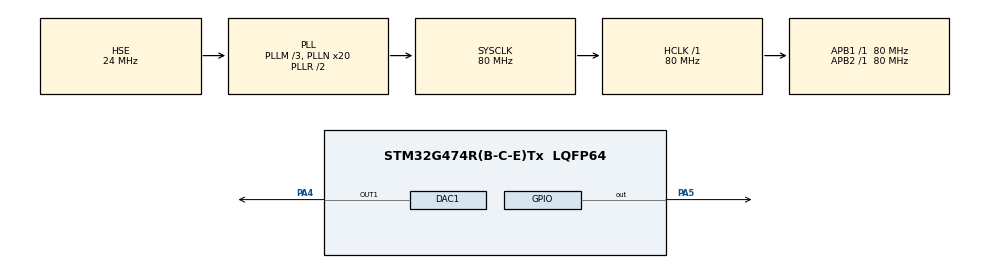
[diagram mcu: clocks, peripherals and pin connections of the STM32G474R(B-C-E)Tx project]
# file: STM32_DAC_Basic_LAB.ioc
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DAC1.DAC_HighFrequency_OUT1-DAC_OUT1=DAC_HIGH_FREQUENCY_INTERFACE_MODE_DISABLE
Mcu.Family=STM32G4
Mcu.Name=STM32G474R(B-C-E)Tx
Mcu.Package=LQFP64
NVIC.PriorityGroup=NVIC_PRIORITYGROUP_4
NVIC.TIM1_UP_TIM16_IRQn=true\:15\:0\:false\:false\:true\:false\:true
NVIC.TimeBase=TIM1_UP_TIM16_IRQn
NVIC.TimeBaseIP=TIM1
PA13.Mode=Serial_Wire
PA13.Signal=SYS_JTMS-SWDIO
PA14.Mode=Serial_Wire
PA14.Signal=SYS_JTCK-SWCLK
PA4.Signal=COMP_DAC11_group
PA5.Signal=GPIO_Output
PF0-OSC_IN.Mode=HSE-External-Oscillator
PF0-OSC_IN.Signal=RCC_OSC_IN
PF1-OSC_OUT.Mode=HSE-External-Oscillator
PF1-OSC_OUT.Signal=RCC_OSC_OUT
ProjectManager.HeapSize=0x200
ProjectManager.StackSize=0x400
ProjectManager.TargetToolchain=STM32CubeIDE
RCC.ADC12Freq_Value=80000000
RCC.ADC345Freq_Value=80000000
RCC.AHBFreq_Value=80000000
RCC.APB1Freq_Value=80000000
RCC.APB1TimFreq_Value=80000000
RCC.APB2Freq_Value=80000000
RCC.APB2TimFreq_Value=80000000
RCC.CortexFreq_Value=80000000
RCC.EXTERNAL_CLOCK_VALUE=12288000
RCC.HCLKFreq_Value=80000000
RCC.HSE_VALUE=24000000
RCC.HSI48_VALUE=48000000
RCC.HSI_VALUE=16000000
RCC.LSE_VALUE=32768
RCC.PLLM=RCC_PLLM_DIV3
RCC.PLLN=20
RCC.PLLSourceVirtual=RCC_PLLSOURCE_HSE
RCC.RTCClockSelection=RCC_RTCCLKSOURCE_LSE
RCC.SYSCLKFreq_VALUE=80000000
RCC.SYSCLKSource=RCC_SYSCLKSOURCE_PLLCLK
RCC.USBFreq_Value=80000000
RCC.VCOOutputFreq_Value=160000000
SH.COMP_DAC11_group.0=DAC1_OUT1,DAC_OUT1
VP_SYS_VS_tim1.Mode=TIM1
board=NUCLEO-G474RE

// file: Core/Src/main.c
/* USER CODE BEGIN Header */
/**
  ******************************************************************************
  * @file           : main.c
  * @brief          : Main program body
  ******************************************************************************
  * @attention
  *
  * <h2><center>&copy; Copyright (c) 2021 STMicroelectronics.
  * All rights reserved.</center></h2>
  *
  * This software component is licensed by ST under BSD 3-Clause license,
  * the "License"; You may not use this file except in compliance with the
  * License. You may obtain a copy of the License at:
  *                        opensource.org/licenses/BSD-3-Clause
  *
  ******************************************************************************
  */
/* USER CODE END Header */
#include "main.h"

DAC_HandleTypeDef hdac1;

void SystemClock_Config(void);
static void MX_GPIO_Init(void);
static void MX_DAC1_Init(void);

int main(void)
{
  /* USER CODE BEGIN 1 */

  float value = 0.2;
  uint32_t var;

  /* USER CODE END 1 */

  /* MCU Configuration--------------------------------------------------------*/

  /* Reset of all peripherals, Initializes the Flash interface and the Systick. */
  HAL_Init();

  /* Configure the system clock */
  SystemClock_Config();

  /* Initialize all configured peripherals */
  MX_GPIO_Init();
  MX_DAC1_Init();
  /* USER CODE BEGIN 2 */
  HAL_DAC_Start(&hdac1, DAC_CHANNEL_1);
  /* USER CODE END 2 */

  /* Infinite loop */
  /* USER CODE BEGIN WHILE */

  while (1)
  {
    var = (uint32_t)(value * (0xfff + 1) / 3.3);
    HAL_DAC_SetValue(&hdac1, DAC_CHANNEL_1, DAC_ALIGN_12B_R, var);
    value += 0.1;
    HAL_Delay(500);
    if (value > 3)
      value = 0.2;
    /* USER CODE END WHILE */

  }
}

void SystemClock_Config(void)
{
  RCC_OscInitTypeDef RCC_OscInitStruct = {0};
  RCC_ClkInitTypeDef RCC_ClkInitStruct = {0};

  /** Configure the main internal regulator output voltage
  */
  HAL_PWREx_ControlVoltageScaling(PWR_REGULATOR_VOLTAGE_SCALE1);
  /** Initializes the RCC Oscillators according to the specified parameters
  * in the RCC_OscInitTypeDef structure.
  */
  RCC_OscInitStruct.OscillatorType = RCC_OSCILLATORTYPE_HSE;
  RCC_OscInitStruct.HSEState = RCC_HSE_ON;
  RCC_OscInitStruct.PLL.PLLState = RCC_PLL_ON;
  RCC_OscInitStruct.PLL.PLLSource = RCC_PLLSOURCE_HSE;
  RCC_OscInitStruct.PLL.PLLM = RCC_PLLM_DIV3;
  RCC_OscInitStruct.PLL.PLLN = 20;
  RCC_OscInitStruct.PLL.PLLP = RCC_PLLP_DIV2;
  RCC_OscInitStruct.PLL.PLLQ = RCC_PLLQ_DIV2;
  RCC_OscInitStruct.PLL.PLLR = RCC_PLLR_DIV2;
  if (HAL_RCC_OscConfig(&RCC_OscInitStruct) != HAL_OK)
  {
    Error_Handler();
  }
  /** Initializes the CPU, AHB and APB buses clocks
  */
  RCC_ClkInitStruct.ClockType = RCC_CLOCKTYPE_HCLK|RCC_CLOCKTYPE_SYSCLK
                              |RCC_CLOCKTYPE_PCLK1|RCC_CLOCKTYPE_PCLK2;
  RCC_ClkInitStruct.SYSCLKSource = RCC_SYSCLKSOURCE_PLLCLK;
  RCC_ClkInitStruct.AHBCLKDivider = RCC_SYSCLK_DIV1;
  RCC_ClkInitStruct.APB1CLKDivider = RCC_HCLK_DIV1;
  RCC_ClkInitStruct.APB2CLKDivider = RCC_HCLK_DIV1;

  if (HAL_RCC_ClockConfig(&RCC_ClkInitStruct, FLASH_LATENCY_2) != HAL_OK)
  {
    Error_Handler();
  }
}

static void MX_DAC1_Init(void)
{

  DAC_ChannelConfTypeDef sConfig = {0};

  /** DAC Initialization
  */
  hdac1.Instance = DAC1;
  if (HAL_DAC_Init(&hdac1) != HAL_OK)
  {
    Error_Handler();
  }
  /** DAC channel OUT1 config
  */
  sConfig.DAC_HighFrequency = DAC_HIGH_FREQUENCY_INTERFACE_MODE_DISABLE;
  sConfig.DAC_DMADoubleDataMode = DISABLE;
  sConfig.DAC_SignedFormat = DISABLE;
  sConfig.DAC_SampleAndHold = DAC_SAMPLEANDHOLD_DISABLE;
  sConfig.DAC_Trigger = DAC_TRIGGER_NONE;
  sConfig.DAC_Trigger2 = DAC_TRIGGER_NONE;
  sConfig.DAC_OutputBuffer = DAC_OUTPUTBUFFER_ENABLE;
  sConfig.DAC_ConnectOnChipPeripheral = DAC_CHIPCONNECT_EXTERNAL;
  sConfig.DAC_UserTrimming = DAC_TRIMMING_FACTORY;
  if (HAL_DAC_ConfigChannel(&hdac1, &sConfig, DAC_CHANNEL_1) != HAL_OK)
  {
    Error_Handler();
  }

}

static void MX_GPIO_Init(void)
{
  GPIO_InitTypeDef GPIO_InitStruct = {0};

  /* GPIO Ports Clock Enable */
  __HAL_RCC_GPIOF_CLK_ENABLE();
  __HAL_RCC_GPIOA_CLK_ENABLE();

  /*Configure GPIO pin Output Level */
  HAL_GPIO_WritePin(GPIOA, GPIO_PIN_5, GPIO_PIN_RESET);

  /*Configure GPIO pin : PA5 */
  GPIO_InitStruct.Pin = GPIO_PIN_5;
  GPIO_InitStruct.Mode = GPIO_MODE_OUTPUT_PP;
  GPIO_InitStruct.Pull = GPIO_NOPULL;
  GPIO_InitStruct.Speed = GPIO_SPEED_FREQ_LOW;
  HAL_GPIO_Init(GPIOA, &GPIO_InitStruct);

}

void HAL_TIM_PeriodElapsedCallback(TIM_HandleTypeDef *htim)
{
  if (htim->Instance == TIM1) {
    HAL_IncTick();
  }
}

void Error_Handler(void)
{
  __disable_irq();
  while (1)
  {
  }
}

/************************ (C) COPYRIGHT STMicroelectronics *****END OF FILE****/
